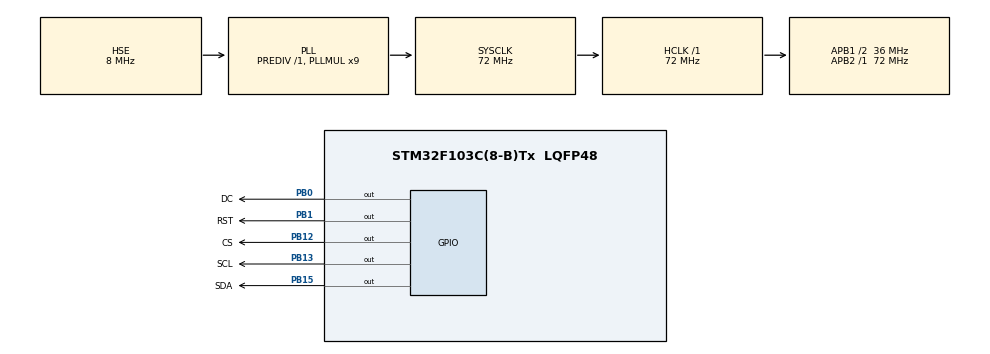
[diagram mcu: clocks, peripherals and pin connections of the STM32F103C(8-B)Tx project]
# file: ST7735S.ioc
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Mcu.Family=STM32F1
Mcu.Name=STM32F103C(8-B)Tx
Mcu.Package=LQFP48
NVIC.PriorityGroup=NVIC_PRIORITYGROUP_4
PA13.Mode=Serial_Wire
PA13.Signal=SYS_JTMS-SWDIO
PA14.Mode=Serial_Wire
PA14.Signal=SYS_JTCK-SWCLK
PB0.GPIO_Label=DC
PB0.Signal=GPIO_Output
PB1.GPIO_Label=RST
PB1.Signal=GPIO_Output
PB12.GPIO_Label=CS
PB12.Signal=GPIO_Output
PB13.GPIO_Label=SCL
PB13.Signal=GPIO_Output
PB15.GPIO_Label=SDA
PB15.Signal=GPIO_Output
PD0-OSC_IN.Mode=HSE-External-Oscillator
PD0-OSC_IN.Signal=RCC_OSC_IN
PD1-OSC_OUT.Mode=HSE-External-Oscillator
PD1-OSC_OUT.Signal=RCC_OSC_OUT
ProjectManager.HeapSize=0x200
ProjectManager.StackSize=0x400
ProjectManager.TargetToolchain=MDK-ARM V5.32
RCC.AHBFreq_Value=72000000
RCC.APB1CLKDivider=RCC_HCLK_DIV2
RCC.APB1Freq_Value=36000000
RCC.APB1TimFreq_Value=72000000
RCC.APB2Freq_Value=72000000
RCC.APB2TimFreq_Value=72000000
RCC.HCLKFreq_Value=72000000
RCC.PLLMUL=RCC_PLL_MUL9
RCC.PLLSourceVirtual=RCC_PLLSOURCE_HSE
RCC.SYSCLKFreq_VALUE=72000000
RCC.SYSCLKSource=RCC_SYSCLKSOURCE_PLLCLK
RCC.USBFreq_Value=72000000
board=custom

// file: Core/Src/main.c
/* USER CODE BEGIN Header */
/**
  ******************************************************************************
  * @file           : main.c
  * @brief          : Main program body
  ******************************************************************************
  * @attention
  *
  * Copyright (c) 2024 STMicroelectronics.
  * All rights reserved.
  *
  * This software is licensed under terms that can be found in the LICENSE file
  * in the root directory of this software component.
  * If no LICENSE file comes with this software, it is provided AS-IS.
  *
  ******************************************************************************
  */
/* USER CODE END Header */
#include "main.h"
#include "gpio.h"

/* USER CODE BEGIN Includes */
#include "Lcd_Driver.h"
//#include "LCD_Config.h"
/* USER CODE END Includes */

void SystemClock_Config(void);

int main(void)
{

  /* MCU Configuration--------------------------------------------------------*/

  /* Reset of all peripherals, Initializes the Flash interface and the Systick. */
  HAL_Init();

  /* Configure the system clock */
  SystemClock_Config();

  /* Initialize all configured peripherals */
  MX_GPIO_Init();
  /* USER CODE BEGIN 2 */
  lcd_init();
  /* USER CODE END 2 */

  /* Infinite loop */
  /* USER CODE BEGIN WHILE */
//  showimage(gImage_zz);
//  HAL_Delay(5000);
showPicture();
HAL_Delay(3000);
lcd_set_color(0XFFFF);
showChinese(2,1, WHITE,BLACK,0);
showChinese(2,2, WHITE,BLACK,2);
showchar(3,1,WHITE,BLACK,'@');
HAL_Delay(3000);
lcd_set_color(0XFFFF);
OLED_ShowString(3,1,WHITE,BLACK,"hello world!");
showChinese(3,7, WHITE,BLACK,0);
showChinese(3,8, WHITE,BLACK,2);
//showChinese(2,2, WHITE,BLACK,2);
//showChinese(2,1, RED,BLACK,0);
//showChinese(2,2, RED,BLACK,2);
//showChinese(2,3, RED,BLACK,0);
//showChinese(2,4, RED,BLACK,2);
//showChinese(2,5, RED,BLACK,0);
//showChinese(2,6, RED,BLACK,2);
//showChinese(2,7, RED,BLACK,0);
//showChinese(2,8, RED,BLACK,2);
//showChinese(2,9, RED,BLACK,0);
//showChinese(2,10,RED,BLACK,2);
//showchar(1,1,RED,BLACK,'a');
//OLED_ShowString(3,1,RED,BLACK,"hello world!");
//showChinese(2,1,GREEN,0);
//showChinese(3,1,BLUE ,0);
//showChinese(4,1,RED  ,0);
//showChinese(5,1,GREEN,0);
//showChinese(6,1,BLUE ,0);
//showChinese(7,1,RED  ,0);
//showChinese(8,1,GREEN,0);
//showChinese(9,1,BLUE  ,0);
//showChinese(10,1,RED,0);
  while (1)
  {
//	  lcd_set_color(GREEN);
//	  HAL_Delay(500);
//	  lcd_set_color(BLUE);
//	  HAL_Delay(500);
//	  lcd_set_color(RED);
//	  HAL_Delay(500);
//	  lcd_set_color(WHITE);
//	  HAL_Delay(500);
//	  lcd_set_color(BLACK);
//	  HAL_Delay(500);
//	  lcd_set_area_color(0,80,100,160,GRAY0);
//	  HAL_Delay(1000);
//	  showimage(gImage_zz);
//	  HAL_Delay(5000);
//	  lcd_draw_line(0,0,128,RED);
//	  lcd_draw_line(0,127,160,GREEN);
    /* USER CODE END WHILE */

  }
}

void SystemClock_Config(void)
{
  RCC_OscInitTypeDef RCC_OscInitStruct = {0};
  RCC_ClkInitTypeDef RCC_ClkInitStruct = {0};

  /** Initializes the RCC Oscillators according to the specified parameters
  * in the RCC_OscInitTypeDef structure.
  */
  RCC_OscInitStruct.OscillatorType = RCC_OSCILLATORTYPE_HSE;
  RCC_OscInitStruct.HSEState = RCC_HSE_ON;
  RCC_OscInitStruct.HSEPredivValue = RCC_HSE_PREDIV_DIV1;
  RCC_OscInitStruct.HSIState = RCC_HSI_ON;
  RCC_OscInitStruct.PLL.PLLState = RCC_PLL_ON;
  RCC_OscInitStruct.PLL.PLLSource = RCC_PLLSOURCE_HSE;
  RCC_OscInitStruct.PLL.PLLMUL = RCC_PLL_MUL9;
  if (HAL_RCC_OscConfig(&RCC_OscInitStruct) != HAL_OK)
  {
    Error_Handler();
  }

  /** Initializes the CPU, AHB and APB buses clocks
  */
  RCC_ClkInitStruct.ClockType = RCC_CLOCKTYPE_HCLK|RCC_CLOCKTYPE_SYSCLK
                              |RCC_CLOCKTYPE_PCLK1|RCC_CLOCKTYPE_PCLK2;
  RCC_ClkInitStruct.SYSCLKSource = RCC_SYSCLKSOURCE_PLLCLK;
  RCC_ClkInitStruct.AHBCLKDivider = RCC_SYSCLK_DIV1;
  RCC_ClkInitStruct.APB1CLKDivider = RCC_HCLK_DIV2;
  RCC_ClkInitStruct.APB2CLKDivider = RCC_HCLK_DIV1;

  if (HAL_RCC_ClockConfig(&RCC_ClkInitStruct, FLASH_LATENCY_2) != HAL_OK)
  {
    Error_Handler();
  }
}

void Error_Handler(void)
{
  __disable_irq();
  while (1)
  {
  }
}
